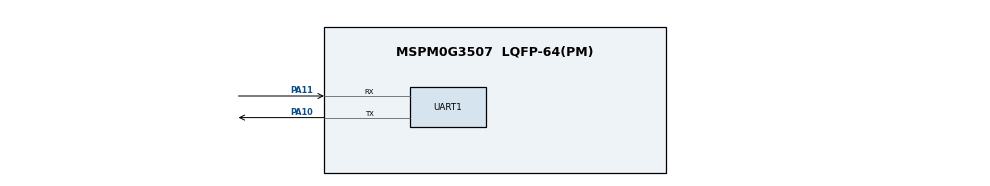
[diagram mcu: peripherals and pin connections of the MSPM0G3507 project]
//@cliArgs --device "MSPM0G350X" --package "LQFP-64(PM)" --part "Default"
//@v2CliArgs --device "MSPM0G3507" --package "LQFP-64(PM)"
// @cliArgs --board /ti/boards/LP_MSPM0G3507 --rtos nortos

/**
 * Import the modules used in this configuration.
 */
const UART  = scripting.addModule("/ti/driverlib/UART", {}, false);
const UART1 = UART.addInstance();

/**
 * Write custom configuration values to the imported modules.
 */
const divider9       = system.clockTree["UDIV"];
divider9.divideValue = 2;

const multiplier2         = system.clockTree["PLL_QDIV"];
multiplier2.multiplyValue = 5;

const mux8       = system.clockTree["HSCLKMUX"];
mux8.inputSelect = "HSCLKMUX_SYSPLL0";

UART1.$name                    = "UART_0";
UART1.rxFifoThreshold          = "DL_UART_RX_FIFO_LEVEL_ONE_ENTRY";
UART1.enableDMARX              = false;
UART1.enableDMATX              = false;
UART1.enabledInterrupts        = ["RX"];
UART1.targetBaudRate           = 115200;
UART1.txFifoThreshold          = "DL_UART_TX_FIFO_LEVEL_ONE_ENTRY";
UART1.enableFIFO               = true;
UART1.peripheral.$assign       = "UART0";
UART1.peripheral.rxPin.$assign = "PA11";
UART1.peripheral.txPin.$assign = "PA10";

const Board           = scripting.addModule("/ti/driverlib/Board", {}, false);
Board.configureUnused = true;

const SYSCTL                 = scripting.addModule("/ti/driverlib/SYSCTL", {}, false);
SYSCTL.powerPolicy           = "STANDBY0";
SYSCTL.forceDefaultClkConfig = true;
SYSCTL.clockTreeEn           = true;
